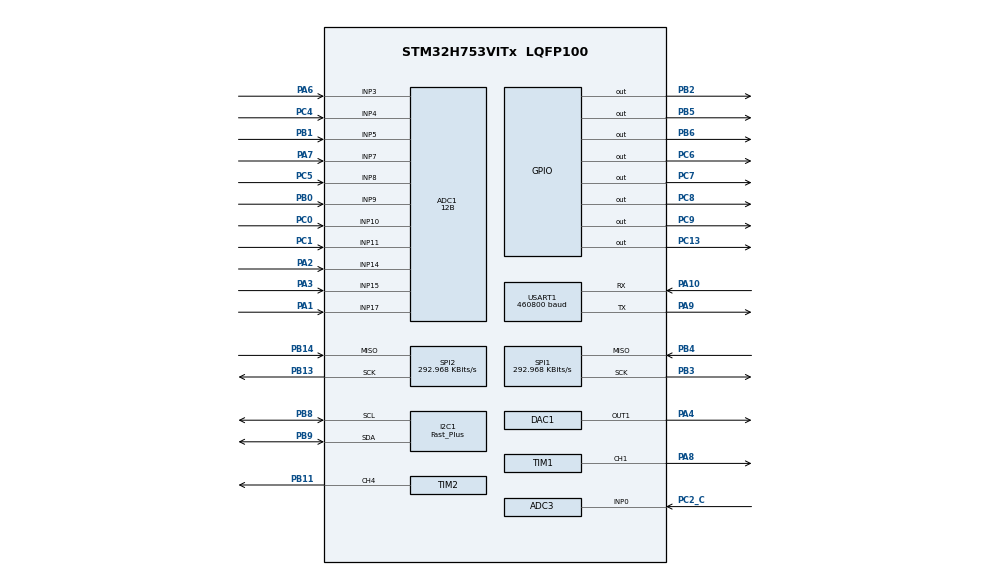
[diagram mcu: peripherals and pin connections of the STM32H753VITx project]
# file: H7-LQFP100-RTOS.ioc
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ADC1.Channel-0\#ChannelRegularConversion=ADC_CHANNEL_3
ADC1.Channel-1\#ChannelRegularConversion=ADC_CHANNEL_4
ADC1.Channel-10\#ChannelRegularConversion=ADC_CHANNEL_17
ADC1.Channel-2\#ChannelRegularConversion=ADC_CHANNEL_5
ADC1.Channel-3\#ChannelRegularConversion=ADC_CHANNEL_7
ADC1.Channel-4\#ChannelRegularConversion=ADC_CHANNEL_8
ADC1.Channel-5\#ChannelRegularConversion=ADC_CHANNEL_9
ADC1.Channel-6\#ChannelRegularConversion=ADC_CHANNEL_10
ADC1.Channel-7\#ChannelRegularConversion=ADC_CHANNEL_11
ADC1.Channel-8\#ChannelRegularConversion=ADC_CHANNEL_14
ADC1.Channel-9\#ChannelRegularConversion=ADC_CHANNEL_15
ADC1.ClockPrescaler=ADC_CLOCK_ASYNC_DIV2
ADC1.ClockPrescalerADC3=ADC_CLOCK_ASYNC_DIV2
ADC1.ContinuousConvMode=ENABLE
ADC1.ConversionDataManagement=ADC_CONVERSIONDATA_DMA_CIRCULAR
ADC1.NbrOfConversion=11
ADC1.NbrOfConversionFlag=1
ADC1.OffsetNumber-0\#ChannelRegularConversion=ADC_OFFSET_NONE
ADC1.OffsetNumber-1\#ChannelRegularConversion=ADC_OFFSET_NONE
ADC1.OffsetNumber-10\#ChannelRegularConversion=ADC_OFFSET_NONE
ADC1.OffsetNumber-2\#ChannelRegularConversion=ADC_OFFSET_NONE
ADC1.OffsetNumber-3\#ChannelRegularConversion=ADC_OFFSET_NONE
ADC1.OffsetNumber-4\#ChannelRegularConversion=ADC_OFFSET_NONE
ADC1.OffsetNumber-5\#ChannelRegularConversion=ADC_OFFSET_NONE
ADC1.OffsetNumber-6\#ChannelRegularConversion=ADC_OFFSET_NONE
ADC1.OffsetNumber-7\#ChannelRegularConversion=ADC_OFFSET_NONE
ADC1.OffsetNumber-8\#ChannelRegularConversion=ADC_OFFSET_NONE
ADC1.OffsetNumber-9\#ChannelRegularConversion=ADC_OFFSET_NONE
ADC1.OffsetSignedSaturation-0\#ChannelRegularConversion=DISABLE
ADC1.Overrun=ADC_OVR_DATA_OVERWRITTEN
ADC1.Rank-0\#ChannelRegularConversion=1
ADC1.Rank-1\#ChannelRegularConversion=2
ADC1.Rank-10\#ChannelRegularConversion=11
ADC1.Rank-2\#ChannelRegularConversion=3
ADC1.Rank-3\#ChannelRegularConversion=4
ADC1.Rank-4\#ChannelRegularConversion=5
ADC1.Rank-5\#ChannelRegularConversion=6
ADC1.Rank-6\#ChannelRegularConversion=7
ADC1.Rank-7\#ChannelRegularConversion=8
ADC1.Rank-8\#ChannelRegularConversion=9
ADC1.Rank-9\#ChannelRegularConversion=10
ADC1.Resolution=ADC_RESOLUTION_12B
ADC1.SamplingTime-0\#ChannelRegularConversion=ADC_SAMPLETIME_810CYCLES_5
ADC1.SamplingTime-1\#ChannelRegularConversion=ADC_SAMPLETIME_810CYCLES_5
ADC1.SamplingTime-10\#ChannelRegularConversion=ADC_SAMPLETIME_810CYCLES_5
ADC1.SamplingTime-2\#ChannelRegularConversion=ADC_SAMPLETIME_810CYCLES_5
ADC1.SamplingTime-3\#ChannelRegularConversion=ADC_SAMPLETIME_810CYCLES_5
ADC1.SamplingTime-4\#ChannelRegularConversion=ADC_SAMPLETIME_810CYCLES_5
ADC1.SamplingTime-5\#ChannelRegularConversion=ADC_SAMPLETIME_810CYCLES_5
ADC1.SamplingTime-6\#ChannelRegularConversion=ADC_SAMPLETIME_810CYCLES_5
ADC1.SamplingTime-7\#ChannelRegularConversion=ADC_SAMPLETIME_810CYCLES_5
ADC1.SamplingTime-8\#ChannelRegularConversion=ADC_SAMPLETIME_810CYCLES_5
ADC1.SamplingTime-9\#ChannelRegularConversion=ADC_SAMPLETIME_810CYCLES_5
ADC1.master=1
ADC3.Channel-0\#ChannelRegularConversion=ADC_CHANNEL_TEMPSENSOR
ADC3.Channel-1\#ChannelRegularConversion=ADC_CHANNEL_VREFINT
ADC3.Channel-2\#ChannelRegularConversion=ADC_CHANNEL_0
ADC3.ClockPrescalerADC3=ADC_CLOCK_ASYNC_DIV2
ADC3.ContinuousConvMode=ENABLE
ADC3.ConversionDataManagement=ADC_CONVERSIONDATA_DMA_CIRCULAR
ADC3.EnableAnalogWatchDog1=false
ADC3.NbrOfConversion=3
ADC3.NbrOfConversionFlag=1
ADC3.OffsetNumber-0\#ChannelRegularConversion=ADC_OFFSET_NONE
ADC3.OffsetNumber-1\#ChannelRegularConversion=ADC_OFFSET_NONE
ADC3.OffsetNumber-2\#ChannelRegularConversion=ADC_OFFSET_NONE
ADC3.OffsetSignedSaturation-0\#ChannelRegularConversion=DISABLE
ADC3.Overrun=ADC_OVR_DATA_OVERWRITTEN
ADC3.Rank-0\#ChannelRegularConversion=1
ADC3.Rank-1\#ChannelRegularConversion=2
ADC3.Rank-2\#ChannelRegularConversion=3
ADC3.Resolution=ADC_RESOLUTION_12B
ADC3.SamplingTime-0\#ChannelRegularConversion=ADC_SAMPLETIME_810CYCLES_5
ADC3.SamplingTime-1\#ChannelRegularConversion=ADC_SAMPLETIME_810CYCLES_5
ADC3.SamplingTime-2\#ChannelRegularConversion=ADC_SAMPLETIME_810CYCLES_5
CORTEX_M7.AccessPermission-Cortex_Memory_Protection_Unit_Region1_Settings=MPU_REGION_FULL_ACCESS
CORTEX_M7.BaseAddress-Cortex_Memory_Protection_Unit_Region0_Settings=0x00
CORTEX_M7.BaseAddress-Cortex_Memory_Protection_Unit_Region1_Settings=0x081C0000
CORTEX_M7.CPU_DCache=Disabled
CORTEX_M7.CPU_ICache=Disabled
CORTEX_M7.DisableExec-Cortex_Memory_Protection_Unit_Region0_Settings=MPU_INSTRUCTION_ACCESS_DISABLE
CORTEX_M7.Enable-Cortex_Memory_Protection_Unit_Region0_Settings=MPU_REGION_ENABLE
CORTEX_M7.Enable-Cortex_Memory_Protection_Unit_Region1_Settings=MPU_REGION_ENABLE
CORTEX_M7.IsShareable-Cortex_Memory_Protection_Unit_Region0_Settings=MPU_ACCESS_SHAREABLE
CORTEX_M7.MPU_Control=__NULL
CORTEX_M7.Size-Cortex_Memory_Protection_Unit_Region0_Settings=MPU_REGION_SIZE_4GB
CORTEX_M7.Size-Cortex_Memory_Protection_Unit_Region1_Settings=MPU_REGION_SIZE_256KB
CORTEX_M7.SubRegionDisable-Cortex_Memory_Protection_Unit_Region0_Settings=0x87
CORTEX_M7.SubRegionDisable-Cortex_Memory_Protection_Unit_Region1_Settings=0x00
CORTEX_M7.TypeExtField-Cortex_Memory_Protection_Unit_Region1_Settings=MPU_TEX_LEVEL1
DAC1.DAC_Channel-DAC_OUT1=DAC_CHANNEL_1
DAC1.DAC_Trigger-DAC_OUT1=DAC_TRIGGER_T2_TRGO
Dma.ADC1.0.Direction=DMA_PERIPH_TO_MEMORY
Dma.ADC1.0.EventEnable=DISABLE
Dma.ADC1.0.FIFOMode=DMA_FIFOMODE_DISABLE
Dma.ADC1.0.Instance=DMA1_Stream0
Dma.ADC1.0.MemDataAlignment=DMA_MDATAALIGN_HALFWORD
Dma.ADC1.0.MemInc=DMA_MINC_ENABLE
Dma.ADC1.0.Mode=DMA_CIRCULAR
Dma.ADC1.0.PeriphDataAlignment=DMA_PDATAALIGN_HALFWORD
Dma.ADC1.0.PeriphInc=DMA_PINC_DISABLE
Dma.ADC1.0.Polarity=HAL_DMAMUX_REQ_GEN_RISING
Dma.ADC1.0.Priority=DMA_PRIORITY_LOW
Dma.ADC1.0.RequestNumber=1
Dma.ADC1.0.SignalID=NONE
Dma.ADC1.0.SyncEnable=DISABLE
Dma.ADC1.0.SyncPolarity=HAL_DMAMUX_SYNC_NO_EVENT
Dma.ADC1.0.SyncRequestNumber=1
Dma.ADC1.0.SyncSignalID=NONE
Dma.ADC3.1.Direction=DMA_PERIPH_TO_MEMORY
Dma.ADC3.1.EventEnable=DISABLE
Dma.ADC3.1.FIFOMode=DMA_FIFOMODE_DISABLE
Dma.ADC3.1.Instance=DMA1_Stream1
Dma.ADC3.1.MemDataAlignment=DMA_MDATAALIGN_HALFWORD
Dma.ADC3.1.MemInc=DMA_MINC_ENABLE
Dma.ADC3.1.Mode=DMA_CIRCULAR
Dma.ADC3.1.PeriphDataAlignment=DMA_PDATAALIGN_HALFWORD
Dma.ADC3.1.PeriphInc=DMA_PINC_DISABLE
Dma.ADC3.1.Polarity=HAL_DMAMUX_REQ_GEN_RISING
Dma.ADC3.1.Priority=DMA_PRIORITY_LOW
Dma.ADC3.1.RequestNumber=1
Dma.ADC3.1.SignalID=NONE
Dma.ADC3.1.SyncEnable=DISABLE
Dma.ADC3.1.SyncPolarity=HAL_DMAMUX_SYNC_NO_EVENT
Dma.ADC3.1.SyncRequestNumber=1
Dma.ADC3.1.SyncSignalID=NONE
Dma.DAC1_CH1.2.Direction=DMA_MEMORY_TO_PERIPH
Dma.DAC1_CH1.2.EventEnable=DISABLE
Dma.DAC1_CH1.2.FIFOMode=DMA_FIFOMODE_DISABLE
Dma.DAC1_CH1.2.Instance=DMA1_Stream5
Dma.DAC1_CH1.2.MemDataAlignment=DMA_MDATAALIGN_WORD
Dma.DAC1_CH1.2.MemInc=DMA_MINC_ENABLE
Dma.DAC1_CH1.2.Mode=DMA_CIRCULAR
Dma.DAC1_CH1.2.PeriphDataAlignment=DMA_PDATAALIGN_WORD
Dma.DAC1_CH1.2.PeriphInc=DMA_PINC_DISABLE
Dma.DAC1_CH1.2.Polarity=HAL_DMAMUX_REQ_GEN_RISING
Dma.DAC1_CH1.2.Priority=DMA_PRIORITY_LOW
Dma.DAC1_CH1.2.RequestNumber=1
Dma.DAC1_CH1.2.SignalID=NONE
Dma.DAC1_CH1.2.SyncEnable=DISABLE
Dma.DAC1_CH1.2.SyncPolarity=HAL_DMAMUX_SYNC_NO_EVENT
Dma.DAC1_CH1.2.SyncRequestNumber=1
Dma.DAC1_CH1.2.SyncSignalID=NONE
Dma.I2C1_RX.7.Direction=DMA_PERIPH_TO_MEMORY
Dma.I2C1_RX.7.EventEnable=DISABLE
Dma.I2C1_RX.7.FIFOMode=DMA_FIFOMODE_DISABLE
Dma.I2C1_RX.7.Instance=DMA1_Stream7
Dma.I2C1_RX.7.MemDataAlignment=DMA_MDATAALIGN_BYTE
Dma.I2C1_RX.7.MemInc=DMA_MINC_ENABLE
Dma.I2C1_RX.7.Mode=DMA_NORMAL
Dma.I2C1_RX.7.PeriphDataAlignment=DMA_PDATAALIGN_BYTE
Dma.I2C1_RX.7.PeriphInc=DMA_PINC_DISABLE
Dma.I2C1_RX.7.Polarity=HAL_DMAMUX_REQ_GEN_RISING
Dma.I2C1_RX.7.Priority=DMA_PRIORITY_VERY_HIGH
Dma.I2C1_RX.7.RequestNumber=1
Dma.I2C1_RX.7.SignalID=NONE
Dma.I2C1_RX.7.SyncEnable=DISABLE
Dma.I2C1_RX.7.SyncPolarity=HAL_DMAMUX_SYNC_NO_EVENT
Dma.I2C1_RX.7.SyncRequestNumber=1
Dma.I2C1_RX.7.SyncSignalID=NONE
Dma.I2C1_TX.6.Direction=DMA_MEMORY_TO_PERIPH
Dma.I2C1_TX.6.EventEnable=DISABLE
Dma.I2C1_TX.6.FIFOMode=DMA_FIFOMODE_DISABLE
Dma.I2C1_TX.6.Instance=DMA1_Stream6
Dma.I2C1_TX.6.MemDataAlignment=DMA_MDATAALIGN_BYTE
Dma.I2C1_TX.6.MemInc=DMA_MINC_ENABLE
Dma.I2C1_TX.6.Mode=DMA_NORMAL
Dma.I2C1_TX.6.PeriphDataAlignment=DMA_PDATAALIGN_BYTE
Dma.I2C1_TX.6.PeriphInc=DMA_PINC_DISABLE
Dma.I2C1_TX.6.Polarity=HAL_DMAMUX_REQ_GEN_RISING
Dma.I2C1_TX.6.Priority=DMA_PRIORITY_VERY_HIGH
Dma.I2C1_TX.6.RequestNumber=1
Dma.I2C1_TX.6.SignalID=NONE
Dma.I2C1_TX.6.SyncEnable=DISABLE
Dma.I2C1_TX.6.SyncPolarity=HAL_DMAMUX_SYNC_NO_EVENT
Dma.I2C1_TX.6.SyncRequestNumber=1
Dma.I2C1_TX.6.SyncSignalID=NONE
Dma.Request0=ADC1
Dma.Request1=ADC3
Dma.Request2=DAC1_CH1
Dma.Request3=USART1_TX
Dma.Request4=SPI2_RX
Dma.Request5=SPI1_RX
Dma.Request6=I2C1_TX
Dma.Request7=I2C1_RX
Dma.SPI1_RX.5.Direction=DMA_PERIPH_TO_MEMORY
Dma.SPI1_RX.5.EventEnable=DISABLE
Dma.SPI1_RX.5.FIFOMode=DMA_FIFOMODE_DISABLE
Dma.SPI1_RX.5.Instance=DMA1_Stream4
Dma.SPI1_RX.5.MemDataAlignment=DMA_MDATAALIGN_HALFWORD
Dma.SPI1_RX.5.MemInc=DMA_MINC_ENABLE
Dma.SPI1_RX.5.Mode=DMA_NORMAL
Dma.SPI1_RX.5.PeriphDataAlignment=DMA_PDATAALIGN_HALFWORD
Dma.SPI1_RX.5.PeriphInc=DMA_PINC_DISABLE
Dma.SPI1_RX.5.Polarity=HAL_DMAMUX_REQ_GEN_RISING
Dma.SPI1_RX.5.Priority=DMA_PRIORITY_LOW
Dma.SPI1_RX.5.RequestNumber=1
Dma.SPI1_RX.5.SignalID=NONE
Dma.SPI1_RX.5.SyncEnable=DISABLE
Dma.SPI1_RX.5.SyncPolarity=HAL_DMAMUX_SYNC_NO_EVENT
Dma.SPI1_RX.5.SyncRequestNumber=1
Dma.SPI1_RX.5.SyncSignalID=NONE
Dma.SPI2_RX.4.Direction=DMA_PERIPH_TO_MEMORY
Dma.SPI2_RX.4.EventEnable=DISABLE
Dma.SPI2_RX.4.FIFOMode=DMA_FIFOMODE_DISABLE
Dma.SPI2_RX.4.Instance=DMA1_Stream3
Dma.SPI2_RX.4.MemDataAlignment=DMA_MDATAALIGN_HALFWORD
Dma.SPI2_RX.4.MemInc=DMA_MINC_ENABLE
Dma.SPI2_RX.4.Mode=DMA_NORMAL
Dma.SPI2_RX.4.PeriphDataAlignment=DMA_PDATAALIGN_HALFWORD
Dma.SPI2_RX.4.PeriphInc=DMA_PINC_DISABLE
Dma.SPI2_RX.4.Polarity=HAL_DMAMUX_REQ_GEN_RISING
Dma.SPI2_RX.4.Priority=DMA_PRIORITY_LOW
Dma.SPI2_RX.4.RequestNumber=1
Dma.SPI2_RX.4.SignalID=NONE
Dma.SPI2_RX.4.SyncEnable=DISABLE
Dma.SPI2_RX.4.SyncPolarity=HAL_DMAMUX_SYNC_NO_EVENT
Dma.SPI2_RX.4.SyncRequestNumber=1
Dma.SPI2_RX.4.SyncSignalID=NONE
Dma.USART1_TX.3.Direction=DMA_MEMORY_TO_PERIPH
Dma.USART1_TX.3.EventEnable=DISABLE
Dma.USART1_TX.3.FIFOMode=DMA_FIFOMODE_DISABLE
Dma.USART1_TX.3.Instance=DMA1_Stream2
Dma.USART1_TX.3.MemDataAlignment=DMA_MDATAALIGN_BYTE
Dma.USART1_TX.3.MemInc=DMA_MINC_ENABLE
Dma.USART1_TX.3.Mode=DMA_NORMAL
Dma.USART1_TX.3.PeriphDataAlignment=DMA_PDATAALIGN_BYTE
Dma.USART1_TX.3.PeriphInc=DMA_PINC_DISABLE
Dma.USART1_TX.3.Polarity=HAL_DMAMUX_REQ_GEN_RISING
Dma.USART1_TX.3.Priority=DMA_PRIORITY_LOW
Dma.USART1_TX.3.RequestNumber=1
Dma.USART1_TX.3.SignalID=NONE
Dma.USART1_TX.3.SyncEnable=DISABLE
Dma.USART1_TX.3.SyncPolarity=HAL_DMAMUX_SYNC_NO_EVENT
Dma.USART1_TX.3.SyncRequestNumber=1
Dma.USART1_TX.3.SyncSignalID=NONE
FREERTOS.INCLUDE_xEventGroupSetBitFromISR=1
FREERTOS.Tasks01=PMT_task,54,128,PMT_init,Default,NULL,Static,PMT_taskBuffer,PMT_taskControlBlock;ERPA_task,55,128,ERPA_init,Default,NULL,Static,ERPA_taskBuffer,ERPA_taskControlBlock;HK_task,52,128,HK_init,Default,NULL,Static,HK_taskBuffer,HK_taskControlBlock;AUTOINIT_task,24,128,AUTOINIT_init,Default,NULL,Static,AUTOINIT_taskBuffer,AUTOINIT_taskControlBlock;AUTODEINIT_task,24,128,AUTODEINIT_init,Default,NULL,Static,AUTODEINIT_taskBuffer,AUTODEINIT_taskControlBlock;Voltage_Monitor,53,128,Voltage_Monitor_init,Default,NULL,Static,Voltage_MonitorBuffer,Voltage_MonitorControlBlock;STOP_task,24,128,STOP_init,Default,NULL,Static,STOP_taskBuffer,STOP_taskControlBlock;Science_task,55,128,Science_init,Default,NULL,Static,Science_taskBuffer,Science_taskControlBlock;Idle_task,55,128,Idle_init,Default,NULL,Static,Idle_taskBuffer,Idle_taskControlBlock;Sync_task,24,128,Sync_init,Default,NULL,Static,Sync_taskBuffer,Sync_taskControlBlock
FREERTOS.configCHECK_FOR_STACK_OVERFLOW=1
FREERTOS.configENABLE_FPU=1
FREERTOS.configUSE_TICK_HOOK=1
I2C1.I2C_Speed_Mode=I2C_Fast_Plus
I2C1.Timing=0x00100517
IWDG1.Prescaler=IWDG_PRESCALER_64
IWDG1.Reload=2499
IWDG1.Window=2499
Mcu.Family=STM32H7
Mcu.Name=STM32H753VITx
Mcu.Package=LQFP100
NVIC.DMA1_Stream0_IRQn=true\:5\:0\:false\:false\:true\:true\:false\:true\:true
NVIC.DMA1_Stream1_IRQn=true\:5\:0\:false\:false\:true\:true\:false\:true\:true
NVIC.DMA1_Stream2_IRQn=true\:5\:0\:false\:false\:true\:true\:false\:true\:true
NVIC.DMA1_Stream3_IRQn=true\:5\:0\:false\:false\:true\:true\:false\:true\:true
NVIC.DMA1_Stream4_IRQn=true\:5\:0\:false\:false\:true\:true\:false\:true\:true
NVIC.DMA1_Stream5_IRQn=true\:5\:0\:false\:false\:true\:false\:false\:true\:true
NVIC.DMA1_Stream6_IRQn=true\:5\:0\:false\:false\:true\:true\:false\:true\:true
NVIC.DMA1_Stream7_IRQn=true\:5\:0\:false\:false\:true\:true\:false\:true\:true
NVIC.FLASH_IRQn=true\:5\:0\:false\:false\:true\:true\:true\:true\:true
NVIC.I2C1_ER_IRQn=true\:5\:0\:false\:false\:true\:true\:true\:true\:true
NVIC.I2C1_EV_IRQn=true\:5\:0\:false\:false\:true\:true\:true\:true\:true
NVIC.PriorityGroup=NVIC_PRIORITYGROUP_4
NVIC.SPI1_IRQn=true\:5\:0\:false\:false\:true\:true\:false\:true\:true
NVIC.SPI2_IRQn=true\:5\:0\:false\:false\:true\:true\:true\:true\:true
NVIC.TIM1_BRK_IRQn=true\:5\:0\:false\:false\:true\:true\:true\:true\:true
NVIC.TIM1_CC_IRQn=true\:5\:0\:false\:false\:true\:true\:true\:true\:true
NVIC.TIM1_TRG_COM_IRQn=true\:5\:0\:false\:false\:true\:true\:true\:true\:true
NVIC.TIM1_UP_IRQn=true\:5\:0\:false\:false\:true\:true\:true\:true\:true
NVIC.TIM2_IRQn=true\:5\:0\:false\:false\:true\:true\:true\:true\:true
NVIC.TIM3_IRQn=true\:5\:0\:false\:false\:true\:true\:true\:true\:true
NVIC.TIM6_DAC_IRQn=true\:5\:0\:true\:false\:true\:false\:false\:true\:true
NVIC.TimeBase=TIM6_DAC_IRQn
NVIC.TimeBaseIP=TIM6
NVIC.USART1_IRQn=true\:5\:0\:false\:false\:true\:true\:true\:true\:true
PA1.Mode=IN17-Single-Ended
PA1.Signal=ADC1_INP17
PA10.Mode=Asynchronous
PA10.Signal=USART1_RX
PA2.Signal=ADCx_INP14
PA3.Signal=ADCx_INP15
PA4.Signal=COMP_DAC11_group
PA6.Signal=ADCx_INP3
PA7.Signal=ADCx_INP7
PA8.Signal=S_TIM1_CH1
PA9.Mode=Asynchronous
PA9.Signal=USART1_TX
PB0.Signal=ADCx_INP9
PB1.Signal=ADCx_INP5
PB11.Signal=S_TIM2_CH4
PB13.Mode=RX_Only_Simplex_Unidirect_Master
PB13.Signal=SPI2_SCK
PB14.Mode=RX_Only_Simplex_Unidirect_Master
PB14.Signal=SPI2_MISO
PB2.GPIO_PuPd=GPIO_PULLDOWN
PB2.Signal=GPIO_Output
PB3\ (JTDO/TRACESWO).Mode=RX_Only_Simplex_Unidirect_Master
PB3\ (JTDO/TRACESWO).Signal=SPI1_SCK
PB4\ (NJTRST).Mode=RX_Only_Simplex_Unidirect_Master
PB4\ (NJTRST).Signal=SPI1_MISO
PB5.GPIO_PuPd=GPIO_PULLDOWN
PB5.Signal=GPIO_Output
PB6.GPIO_PuPd=GPIO_PULLDOWN
PB6.Signal=GPIO_Output
PB8.Mode=I2C
PB8.Signal=I2C1_SCL
PB9.Mode=I2C
PB9.Signal=I2C1_SDA
PC0.Signal=ADCx_INP10
PC1.Signal=ADCx_INP11
PC13.GPIO_PuPd=GPIO_PULLDOWN
PC13.Signal=GPIO_Output
PC14-OSC32_IN\ (OSC32_IN).Mode=LSE-External-Oscillator
PC14-OSC32_IN\ (OSC32_IN).Signal=RCC_OSC32_IN
PC15-OSC32_OUT\ (OSC32_OUT).Mode=LSE-External-Oscillator
PC15-OSC32_OUT\ (OSC32_OUT).Signal=RCC_OSC32_OUT
PC2_C.Mode=IN0-Single-Ended
PC2_C.Signal=ADC3_INP0
PC4.Signal=ADCx_INP4
PC5.Signal=ADCx_INP8
PC6.GPIO_PuPd=GPIO_PULLDOWN
PC6.Signal=GPIO_Output
PC7.GPIO_PuPd=GPIO_PULLDOWN
PC7.Signal=GPIO_Output
PC8.GPIO_PuPd=GPIO_PULLDOWN
PC8.Signal=GPIO_Output
PC9.GPIO_PuPd=GPIO_PULLDOWN
PC9.Signal=GPIO_Output
PH0-OSC_IN\ (PH0).Mode=HSE-External-Oscillator
PH0-OSC_IN\ (PH0).Signal=RCC_OSC_IN
PH1-OSC_OUT\ (PH1).Mode=HSE-External-Oscillator
PH1-OSC_OUT\ (PH1).Signal=RCC_OSC_OUT
ProjectManager.HeapSize=0x200
ProjectManager.StackSize=0x400
ProjectManager.TargetToolchain=STM32CubeIDE
RAMECC.Instance-RAMECC1_Monitor1=RAMECC1_Monitor1
RAMECC.Instance-RAMECC1_Monitor2=RAMECC1_Monitor2
RAMECC.Instance-RAMECC1_Monitor3=RAMECC1_Monitor3
RAMECC.Instance-RAMECC1_Monitor4=RAMECC1_Monitor4
RAMECC.Instance-RAMECC1_Monitor5=RAMECC1_Monitor5
RAMECC.Instance-RAMECC2_Monitor1=RAMECC2_Monitor1
RAMECC.Instance-RAMECC2_Monitor2=RAMECC2_Monitor2
RAMECC.Instance-RAMECC2_Monitor3=RAMECC2_Monitor3
RAMECC.Instance-RAMECC2_Monitor4=RAMECC2_Monitor4
RAMECC.Instance-RAMECC2_Monitor5=RAMECC2_Monitor5
RAMECC.Instance-RAMECC3_Monitor1=RAMECC3_Monitor1
RAMECC.Instance-RAMECC3_Monitor2=RAMECC3_Monitor2
RCC.ADCFreq_Value=18750000
RCC.APB1Freq_Value=37500000
RCC.APB2Freq_Value=75000000
RCC.APB3Freq_Value=75000000
RCC.APB4Freq_Value=75000000
RCC.CortexFreq_Value=75000000
RCC.D2PPRE1=RCC_APB1_DIV2
RCC.DIVM1=4
RCC.DIVM2=4
RCC.DIVM3=4
RCC.DIVN1=24
RCC.DIVN2=24
RCC.DIVN3=24
RCC.DIVP2=8
RCC.HCLKFreq_Value=75000000
RCC.HSIDiv=RCC_PLLSAIDIVR_2
RCC.PLL2FRACN=0
RCC.PLL2_VCI_Range-AdvancedSettings=RCC_PLL2VCIRANGE_0
RCC.PLL3FRACN=0
RCC.PLLFRACN=0
RCC.PLLSourceVirtual=RCC_PLLSOURCE_HSE
RCC.ProductRev=revV
RCC.RCC_RTC_Clock_Source_FROM_HSE=RCC_RTCCLKSOURCE_HSE_DIV25
RCC.RTCClockSelection=RCC_RTCCLKSOURCE_HSE_DIV25
RCC.SYSCLKFreq_VALUE=75000000
RCC.SYSCLKSource=RCC_SYSCLKSOURCE_PLLCLK
RCC.USART16CLockSelection=RCC_USART16CLKSOURCE_HSI
RCC.USBFreq_Value=75000000
RTC.AsynchPrediv=100-1
RTC.SynchPrediv=10000-1
SH.ADCx_INP10.0=ADC1_INP10,IN10-Single-Ended
SH.ADCx_INP11.0=ADC1_INP11,IN11-Single-Ended
SH.ADCx_INP14.0=ADC1_INP14,IN14-Single-Ended
SH.ADCx_INP15.0=ADC1_INP15,IN15-Single-Ended
SH.ADCx_INP3.0=ADC1_INP3,IN3-Single-Ended
SH.ADCx_INP4.0=ADC1_INP4,IN4-Single-Ended
SH.ADCx_INP5.0=ADC1_INP5,IN5-Single-Ended
SH.ADCx_INP7.0=ADC1_INP7,IN7-Single-Ended
SH.ADCx_INP8.0=ADC1_INP8,IN8-Single-Ended
SH.ADCx_INP9.0=ADC1_INP9,IN9-Single-Ended
SH.COMP_DAC11_group.0=DAC1_OUT1,DAC_OUT1
SH.S_TIM1_CH1.0=TIM1_CH1,PWM Generation1 CH1
SH.S_TIM2_CH4.0=TIM2_CH4,PWM Generation4 CH4
SPI1.BaudRatePrescaler=SPI_BAUDRATEPRESCALER_256
SPI1.CalculateBaudRate=292.968 KBits/s
SPI1.DataSize=SPI_DATASIZE_16BIT
SPI1.Direction=SPI_DIRECTION_2LINES_RXONLY
SPI1.Mode=SPI_MODE_MASTER
SPI1.VirtualType=VM_MASTER
SPI2.BaudRatePrescaler=SPI_BAUDRATEPRESCALER_256
SPI2.CalculateBaudRate=292.968 KBits/s
SPI2.DataSize=SPI_DATASIZE_16BIT
SPI2.Direction=SPI_DIRECTION_2LINES_RXONLY
SPI2.Mode=SPI_MODE_MASTER
SPI2.VirtualType=VM_MASTER
TIM1.Channel-PWM\ Generation1\ CH1=TIM_CHANNEL_1
TIM1.Period=62500-1
TIM1.Prescaler=75-1
TIM1.Pulse-PWM\ Generation1\ CH1=480-1
TIM2.AutoReloadPreload=TIM_AUTORELOAD_PRELOAD_ENABLE
TIM2.Channel-PWM\ Generation4\ CH4=TIM_CHANNEL_4
TIM2.Period=3125-1
TIM2.Prescaler=75-1
TIM2.TIM_MasterOutputTrigger=TIM_TRGO_UPDATE
TIM3.Period=35000-1
TIM3.Prescaler=7500-1
USART1.BaudRate=460800
USART1.VirtualMode-Asynchronous=VM_ASYNC
VP_ADC3_TempSens_Input.Mode=IN-TempSens
VP_ADC3_Vref_Input.Mode=IN-Vrefint
VP_FREERTOS_VS_CMSIS_V2.Mode=CMSIS_V2
VP_IWDG1_VS_IWDG.Mode=IWDG_Activate
VP_RAMECC_VS_D1_1.Mode=RAMECC1_Monitor1
VP_RAMECC_VS_D1_2.Mode=RAMECC1_Monitor2
VP_RAMECC_VS_D1_3.Mode=RAMECC1_Monitor3
VP_RAMECC_VS_D1_4.Mode=RAMECC1_Monitor4
VP_RAMECC_VS_D1_5.Mode=RAMECC1_Monitor5
VP_RAMECC_VS_D2_1.Mode=RAMECC2_Monitor1
VP_RAMECC_VS_D2_2.Mode=RAMECC2_Monitor2
VP_RAMECC_VS_D2_3.Mode=RAMECC2_Monitor3
VP_RAMECC_VS_D2_4.Mode=RAMECC2_Monitor4
VP_RAMECC_VS_D2_5.Mode=RAMECC2_Monitor5
VP_RAMECC_VS_D3_1.Mode=RAMECC3_Monitor1
VP_RAMECC_VS_D3_2.Mode=RAMECC3_Monitor2
VP_RTC_VS_RTC_Activate.Mode=RTC_Enabled
VP_RTC_VS_RTC_Calendar.Mode=RTC_Calendar
VP_SYS_VS_tim6.Mode=TIM6
VP_TIM1_VS_ClockSourceINT.Mode=Internal
VP_TIM2_VS_ClockSourceINT.Mode=Internal
VP_TIM3_VS_ClockSourceINT.Mode=Internal
board=custom

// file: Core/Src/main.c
/* USER CODE BEGIN Header */
/**
 ******************************************************************************
 * @file           : main.c
 * @author 		   : Jared Morrison
 * @version 	   : 1.0.0
 * @brief          : Main program body
 ******************************************************************************
 * @attention
 *
 * Copyright (c) 2024 STMicroelectronics.
 * All rights reserved.
 *
 * This software is licensed under terms that can be found in the LICENSE file
 * in the root directory of this software component.
 * If no LICENSE file comes with this software, it is provided AS-IS.
 *
 ******************************************************************************
 */
/* USER CODE END Header */
#include "version_info.h"
#include "main.h"
#include "cmsis_os.h"
#include "adc.h"
#include "dac.h"
#include "dma.h"
#include "i2c.h"
#include "iwdg.h"
#include "ramecc.h"
#include "rtc.h"
#include "spi.h"
#include "tim.h"
#include "usart.h"
#include "gpio.h"

/* USER CODE BEGIN PTD */

/**
 * @brief Enumeration of predefined DAC values.
 *        Represents specific output values for the DAC.
 */
typedef enum
{
    DAC_VALUE_0 = 0,
    DAC_VALUE_620 = 620,
    DAC_VALUE_1241 = 1241,
    DAC_VALUE_1861 = 1861,
    DAC_VALUE_2482 = 2482,
    DAC_VALUE_3103 = 3103,
    DAC_VALUE_3723 = 3723,
    DAC_VALUE_4095 = 4095
} DAC_VALUES;

/**
 * @brief Enumeration of accepted command codes.
 *        Defines a set of command values for controlling system power, modes, and error handling.
 */
typedef enum
{
	CMD_SDN1_ON = 0x10,
	CMD_SDN1_OFF = 0x00,
	CMD_SYS_ON = 0x11,
	CMD_SYS_OFF = 0x01,
	CMD_5V_ON = 0x12,
	CMD_5V_OFF = 0x02,
	CMD_N3V3_ON = 0x13,
	CMD_N3V3_OFF = 0x03,
	CMD_N5V_ON = 0x14,
	CMD_N5V_OFF = 0x04,
	CMD_15V_ON = 0x15,
	CMD_15V_OFF = 0x05,
	CMD_N200V_ON = 0x16,
	CMD_N200V_OFF = 0x06,
	CMD_N800V_ON = 0x17,
	CMD_N800V_OFF = 0x07,
	CMD_AUTOSWEEP_ON = 0x18,
	CMD_AUTOSWEEP_OFF = 0x08,
	CMD_ERPA_ON = 0x19,
	CMD_ERPA_OFF = 0x09,
	CMD_PMT_ON = 0x1A,
	CMD_PMT_OFF = 0x0A,
	CMD_HK_ON = 0x1B,
	CMD_HK_OFF = 0x0B,
	CMD_STEP_UP = 0x1C,
	CMD_STEP_DOWN = 0x0C,
	CMD_FACTOR_UP = 0x1D,
	CMD_FACTOR_DOWN = 0x0D,
	CMD_AUTO_INIT = 0x1E,
	CMD_AUTO_DEINIT = 0x0E,
	CMD_SYNC_MODE = 0xA0,
	CMD_SCIENCE_MODE = 0xA1,
	CMD_IDLE_MODE = 0xA2,
	CMD_ENTER_STOP = 0xA3,
	CMD_RESET_ERROR_COUNTERS = 0xA4,
	CMD_SEND_PREVIOUS_ERROR = 0xA5,
	CMD_SEND_VERSION_PACKET = 0xA6,
	CMD_SEND_VERSION_INFO = 0xA7,
	CMD_UPDATE_FIRMWARE = 0x2A,
	CMD_ST_BL_SYNC = 0x7F
}ACCEPTED_COMMANDS;

typedef  void (*pFunction)(void);
/* USER CODE END PTD */

/* USER CODE BEGIN PD */
//#define HK_100MS_COUNTER_MAX 32
#define HK_100MS_COUNTER_MAX 3200

#define ACK 0xFF
#define NACK 0x00

#define BOOTLOADER_FLAG_ADDR ((uint32_t*)0x2001FFF0)
#define BOOTLOADER_FLAG_VALUE 0xDEADBEEF
#define BOOTLOADER_FLAG_OFFSET 1000
#define BOOTLOADER_ADDRESS 0x1FF09800
/* USER CODE END PD */

/* USER CODE BEGIN PV */

/**
 * @brief Array of GPIO pin configurations.
 *        Represents the mapping of specific GPIO ports and pins to system components.
 */
const gpio_pins gpios[] =
{
		{ GPIOB, GPIO_PIN_2 	},	// 0 -- SDN1
		{ GPIOB, GPIO_PIN_5 	},	// 1 -- SYS_ON
		{ GPIOC, GPIO_PIN_7 	},	// 2 -- 5v_EN
		{ GPIOC, GPIO_PIN_6 	},	// 3 -- N3V3_EN
		{ GPIOC, GPIO_PIN_8 	},	// 4 -- N5V_EN
		{ GPIOC, GPIO_PIN_9 	},	// 5 -- 15V_EN
		{ GPIOC, GPIO_PIN_13 	},	// 6 -- N150V_EN
		{ GPIOB, GPIO_PIN_6 	}	// 7 -- 800HVON
};

/**
 * @brief Array of DAC output values representing sweeping up and down voltages.
 *
 * DAC_OUT alternates between specified DAC values to control the output voltage.
 * The first half sweeps up, reaching a maximum at DAC_VALUE_4095, then sweeps down.
 */
uint32_t DAC_OUT[DAC_OUT_ARRAY_SIZE] =
{
		DAC_VALUE_0, DAC_VALUE_0,		// |	Sweeping Up
		DAC_VALUE_620, DAC_VALUE_620,	// |
		DAC_VALUE_1241, DAC_VALUE_1241,	// |
		DAC_VALUE_1861, DAC_VALUE_1861,	// |
		DAC_VALUE_2482, DAC_VALUE_2482,	// |
		DAC_VALUE_3103, DAC_VALUE_3103,	// |
		DAC_VALUE_3723, DAC_VALUE_3723,	// V

		DAC_VALUE_4095, DAC_VALUE_4095,	// --	Max Sweep
		DAC_VALUE_4095, DAC_VALUE_4095, // --

		DAC_VALUE_3723, DAC_VALUE_3723,	// |	Sweeping Down
		DAC_VALUE_3103, DAC_VALUE_3103,	// |
		DAC_VALUE_2482, DAC_VALUE_2482,	// |
		DAC_VALUE_1861, DAC_VALUE_1861,	// |
		DAC_VALUE_1241, DAC_VALUE_1241,	// |
		DAC_VALUE_620, DAC_VALUE_620,	// |
		DAC_VALUE_0, DAC_VALUE_0		// V
}; // For 3.3 volts

osEventFlagsId_t packet_event_flags;
osEventFlagsId_t utility_event_flags;
osEventFlagsId_t mode_event_flags;

unsigned char UART_RX_BUFFER[UART_RX_BUFFER_SIZE];
volatile uint8_t HK_ENABLED = DISABLED;
volatile uint8_t ERPA_ENABLED = DISABLED;
volatile uint8_t step = 0;
volatile uint32_t cadence = 3125;
volatile uint32_t uptime_millis = 0;
volatile uint32_t HK_100_ms_counter = 0;
volatile uint8_t IDLING = 1;
volatile uint8_t startup_pmt_sent = 0;
volatile uint8_t startup_hk_sent = 0;

extern int _estack;
uint32_t *bootloader_flag;
pFunction JumpToApplication;
uint32_t JumpAddress;

__attribute__((section(".app_crc"))) __attribute__((used))
const uint32_t app_crc_placeholder = 0xFFFFFFFF;
/* USER CODE END PV */

void SystemClock_Config(void);
void PeriphCommonClock_Config(void);
void MX_FREERTOS_Init(void);
/* USER CODE BEGIN PFP */
void system_setup();
void init_flash_ecc();
/* USER CODE END PFP */

/* USER CODE BEGIN 0 */

/**
 * @brief Prepares for system reset and jump to bootloader
 */
void SetBootloaderFlag() {
	__disable_irq();
//	*bootloader_flag = BOOTLOADER_FLAG_VALUE;
	*BOOTLOADER_FLAG_ADDR = BOOTLOADER_FLAG_VALUE;
	HAL_UART_DeInit(&huart1);
	HAL_NVIC_SystemReset();
}

/**
 * @brief Recognizes if we want to jump to the bootloader and does so
 */
void JumpToBootloader(void)
{
	bootloader_flag = (uint32_t*) (&_estack - BOOTLOADER_FLAG_OFFSET); // below top of stack
	if (*bootloader_flag == BOOTLOADER_FLAG_VALUE) {
		*bootloader_flag = 0;
		/* Jump to system memory bootloader */
		JumpAddress = *(__IO uint32_t*) (BOOTLOADER_ADDRESS + 4);
		JumpToApplication = (pFunction) JumpAddress;
		__set_MSP(*(__IO uint32_t*) BOOTLOADER_ADDRESS);
		JumpToApplication();
	}
		*bootloader_flag = 0; // So next boot won't be affected
}

/**
 * @brief Callback function for handling ECC correction in flash memory.
 *        Detects and handles single-bit flash ECC errors.
 */
void HAL_FLASHEx_EccCorrectionCallback()
{
	ERROR_STRUCT error;
	error.category = EC_seu;
	error.detail = ED_single_bit_error_flash;
	handle_error(error);
}

/**
 * @brief Callback function for handling ECC detection in flash memory.
 *        Detects and handles double-bit flash ECC errors.
 */
void HAL_FLASHEx_EccDetectionCallback()
{
	ERROR_STRUCT error;
	error.category = EC_seu;
	error.detail = ED_double_bit_error_flash;
	handle_error(error);
}

/**
 * @brief Output compare callback for handling timer events.
 *        Sets event flags based on the triggered timer and manages housekeeping tasks.
 *
 * @param htim Pointer to the timer handle triggering the callback.
 */
void HAL_TIM_OC_DelayElapsedCallback(TIM_HandleTypeDef *htim)
{
	if (htim == &htim1)
	{
		// Not the prettiest or best way to go about it, but
		// this will make a startup packet for HK and PMT (NO ERPA STARTUP) when right when science mode is triggered
		if (startup_pmt_sent == 0)
		{
			pmt_seq = 0;
			startup_pmt_sent = 1;
			hk_seq = 0;
			osEventFlagsSet(packet_event_flags, HK_FLAG);
		}
		osEventFlagsSet(packet_event_flags, PMT_FLAG);
	}
	else if (htim == &htim2)
	{
		if (ERPA_ENABLED)
		{
			osEventFlagsSet(packet_event_flags, ERPA_FLAG);
		}
		if (HK_100_ms_counter == HK_100MS_COUNTER_MAX)
		{
			osEventFlagsSet(utility_event_flags, VOLTAGE_MONITOR_FLAG);
			if (HK_ENABLED)
			{
				osEventFlagsSet(packet_event_flags, HK_FLAG);
			}
			HK_100_ms_counter = 0;
		}
		HK_100_ms_counter++;
	}
	else
	{
		// Unknown timer interrupt
	}
}

/**
 * @brief UART receive complete callback.
 *        Processes received commands to control GPIO pins and manage power rails.
 *
 * @param huart Pointer to the UART handle triggering the callback.
 */
void HAL_UART_RxCpltCallback(UART_HandleTypeDef *huart)
{
	HAL_UART_Receive_IT(&huart1, UART_RX_BUFFER, 1);
	uint8_t key_index = 0;
	unsigned char key = UART_RX_BUFFER[key_index];

	switch (key)
	{
	case CMD_SDN1_ON:
	{
		HAL_GPIO_WritePin(gpios[GPIOS_INDEX_SDN1].gpio, gpios[GPIOS_INDEX_SDN1].pin, GPIO_PIN_SET);
		break;
	}

	case CMD_SDN1_OFF:
	{
		HAL_GPIO_WritePin(gpios[GPIOS_INDEX_SDN1].gpio, gpios[GPIOS_INDEX_SDN1].pin, GPIO_PIN_RESET);
		break;
	}

	case CMD_SYS_ON:
	{
		HAL_GPIO_WritePin(gpios[GPIOS_INDEX_SYS].gpio, gpios[GPIOS_INDEX_SYS].pin, GPIO_PIN_SET);
		set_rail_monitor_enable(RAIL_2v5, ENABLED);
		break;
	}

	case CMD_SYS_OFF:
	{
		for (int i = GPIOS_INDEX_N800V; i > GPIOS_INDEX_SDN1; i--)
		{
			HAL_GPIO_WritePin(gpios[i].gpio, gpios[i].pin, GPIO_PIN_RESET);
		}

		for (int i = RAIL_n800v; i >= RAIL_2v5; i--)
		{
			set_rail_monitor_enable(i, DISABLED);
		}
		break;
	}

	case CMD_5V_ON:
	{
		HAL_GPIO_WritePin(gpios[GPIOS_INDEX_5V].gpio, gpios[GPIOS_INDEX_5V].pin, GPIO_PIN_SET);
		set_rail_monitor_enable(RAIL_5v, ENABLED);
		break;
	}

	case CMD_5V_OFF:
	{
		HAL_GPIO_WritePin(gpios[GPIOS_INDEX_5V].gpio, gpios[GPIOS_INDEX_5V].pin, GPIO_PIN_RESET);
		set_rail_monitor_enable(RAIL_5v, DISABLED);
		break;
	}

	case CMD_N3V3_ON:
	{
		HAL_GPIO_WritePin(gpios[GPIOS_INDEX_N3V3].gpio, gpios[GPIOS_INDEX_N3V3].pin, GPIO_PIN_SET);
		set_rail_monitor_enable(RAIL_n3v3, ENABLED);
		break;
	}

	case CMD_N3V3_OFF:
	{
		HAL_GPIO_WritePin(gpios[GPIOS_INDEX_N3V3].gpio, gpios[GPIOS_INDEX_N3V3].pin, GPIO_PIN_RESET);
		set_rail_monitor_enable(RAIL_n3v3, DISABLED);
		break;
	}

	case CMD_N5V_ON:
	{
		HAL_GPIO_WritePin(gpios[GPIOS_INDEX_N5V].gpio, gpios[GPIOS_INDEX_N5V].pin, GPIO_PIN_SET);
		set_rail_monitor_enable(RAIL_n5v, ENABLED);
		break;
	}

	case CMD_N5V_OFF:
	{
		HAL_GPIO_WritePin(gpios[GPIOS_INDEX_N5V].gpio, gpios[GPIOS_INDEX_N5V].pin, GPIO_PIN_RESET);
		set_rail_monitor_enable(RAIL_n5v, DISABLED);
		break;
	}

	case CMD_15V_ON:
	{
		HAL_GPIO_WritePin(gpios[GPIOS_INDEX_15V].gpio, gpios[GPIOS_INDEX_15V].pin, GPIO_PIN_SET);
		set_rail_monitor_enable(RAIL_15v, ENABLED);
		break;
	}

	case CMD_15V_OFF:
	{
		HAL_GPIO_WritePin(gpios[GPIOS_INDEX_15V].gpio, gpios[GPIOS_INDEX_15V].pin, GPIO_PIN_RESET);
		set_rail_monitor_enable(RAIL_15v, DISABLED);
		break;
	}

	case CMD_N200V_ON:
	{
		HAL_GPIO_WritePin(gpios[GPIOS_INDEX_N200V].gpio, gpios[GPIOS_INDEX_N200V].pin, GPIO_PIN_SET);
		set_rail_monitor_enable(RAIL_n200v, ENABLED);
		break;
	}

	case CMD_N200V_OFF:
	{
		HAL_GPIO_WritePin(gpios[GPIOS_INDEX_N200V].gpio, gpios[GPIOS_INDEX_N200V].pin, GPIO_PIN_RESET);
		set_rail_monitor_enable(RAIL_n200v, DISABLED);
		break;
	}

	case CMD_N800V_ON:
	{
		HAL_GPIO_WritePin(gpios[GPIOS_INDEX_N800V].gpio, gpios[GPIOS_INDEX_N800V].pin, GPIO_PIN_SET);
		set_rail_monitor_enable(RAIL_n800v, ENABLED);
		break;
	}

	case CMD_N800V_OFF:
	{
		HAL_GPIO_WritePin(gpios[GPIOS_INDEX_N800V].gpio, gpios[GPIOS_INDEX_N800V].pin, GPIO_PIN_RESET);
		set_rail_monitor_enable(RAIL_n800v, DISABLED);
		break;
	}

	case CMD_AUTOSWEEP_ON:
	{
		HAL_DAC_Start_DMA(&hdac1, DAC_CHANNEL_1, DAC_OUT, DAC_OUT_ARRAY_SIZE, DAC_ALIGN_12B_R);
		break;
	}

	case CMD_AUTOSWEEP_OFF:
	{
		HAL_DAC_Stop_DMA(&hdac1, DAC_CHANNEL_1);
		break;
	}

	case CMD_ERPA_ON:
	{
		osEventFlagsSet(packet_event_flags, ERPA_FLAG);
		TIM2->CCR4 = ERPA_PWM_FREQ;
		ERPA_ENABLED = ENABLED;
		break;
	}

	case CMD_ERPA_OFF:
	{
		ERPA_ENABLED = DISABLED;
		TIM2->CCR4 = 0;
		break;
	}

	case CMD_PMT_ON:
	{
		HAL_TIM_OC_Start_IT(&htim1, TIM_CHANNEL_1);
		osEventFlagsSet(packet_event_flags, PMT_FLAG);
		break;
	}

	case CMD_PMT_OFF:
	{
		HAL_TIM_OC_Stop_IT(&htim1, TIM_CHANNEL_1);
		break;
	}

	case CMD_HK_ON:
	{
		osEventFlagsSet(packet_event_flags, HK_FLAG);
		HK_ENABLED = ENABLED;
		break;
	}

	case CMD_HK_OFF:
	{
		HK_ENABLED = DISABLED;
		break;
	}

	case CMD_STEP_UP:
	{
		if (step < 14)
		{
			step += 2;
			HAL_DAC_SetValue(&hdac1, DAC_CHANNEL_1, DAC_ALIGN_12B_R,
					DAC_OUT[step]);
			HAL_DAC_Start(&hdac1, DAC_CHANNEL_1);
		}
		break;
	}

	case CMD_STEP_DOWN:
	{
		if (step > 1)
		{
			step -= 2;
			HAL_DAC_SetValue(&hdac1, DAC_CHANNEL_1, DAC_ALIGN_12B_R,
					DAC_OUT[step]);
			HAL_DAC_Start(&hdac1, DAC_CHANNEL_1);
		}
		break;
	}

	case CMD_FACTOR_UP:
	{
		if (cadence <= 50000)
		{
			cadence *= 2;
			TIM2->ARR = cadence;
		}
		break;
	}

	case CMD_FACTOR_DOWN:
	{
		if (cadence >= 6250)
		{
			cadence /= 2;
			TIM2->ARR = cadence;
		}
		break;
	}

	case CMD_ENTER_STOP:
	{
		osEventFlagsSet(utility_event_flags, STOP_FLAG);
		break;
	}

	case CMD_AUTO_INIT:
	{
		osEventFlagsSet(utility_event_flags, AUTOINIT_FLAG);
		break;
	}

	case CMD_AUTO_DEINIT:
	{
		osEventFlagsSet(utility_event_flags, AUTODEINIT_FLAG);
		break;
	}

	case CMD_SYNC_MODE:
	{
		osEventFlagsSet(mode_event_flags, SYNC_FLAG);
		break;
	}

	case CMD_SCIENCE_MODE:
	{
		osEventFlagsSet(mode_event_flags, SCIENCE_FLAG);
		break;
	}

	case CMD_IDLE_MODE:
	{
		osEventFlagsSet(mode_event_flags, IDLE_FLAG);
		break;
	}

	case CMD_RESET_ERROR_COUNTERS:
	{
		reset_error_counters();
		break;
	}

	case CMD_SEND_PREVIOUS_ERROR:
	{
#ifdef ERROR_HANDLING_ENABLED
		send_previous_error_packet();
#endif
		break;
	}

	case CMD_SEND_VERSION_PACKET:
	{
		create_version_packet();
		break;
	}

	case CMD_SEND_VERSION_INFO:
	{
		// Ensure the GIT_INFO macro is defined
		#ifdef GIT_COMMIT_HASH
			// Transmit the version information via UART
			HAL_UART_Transmit(&huart1, (uint8_t*)GIT_INFO, strlen(GIT_INFO), HAL_MAX_DELAY);
		#else
			// Transmit a fallback message if version information is unavailable
			const char* fallback_message = "Version information unavailable.\r\n";
			HAL_UART_Transmit(&huart1, (uint8_t*)fallback_message, strlen(fallback_message), HAL_MAX_DELAY);
		#endif
		break;
	}

	case CMD_UPDATE_FIRMWARE:
	{
		uint8_t msg = 0x79;
		HAL_UART_Transmit(&huart1, &msg, 1, 1000);
		SetBootloaderFlag();
		break;
	}

	case CMD_ST_BL_SYNC:
	{
	    uint8_t ack = 0x79;
	    HAL_UART_Transmit(&huart1, &ack, 1, 1000);
	    break;
	}

	default:
	{
		// Unknown command
		break;
	}
	}
}

/**
 * @brief Retrieves and handles the cause of a system reset.
 *        Checks for watchdog and brownout reset conditions and reports errors.
 */
ERROR_STRUCT get_reset_cause()
{
	ERROR_STRUCT error;
	error.category = EC_UNDEFINED;
	error.detail = ED_UNDEFINED;

	if (__HAL_RCC_GET_FLAG(RCC_FLAG_IWDG1RST))
    {
        error.category = EC_watchdog;
        error.detail = ED_UNDEFINED;
        __HAL_RCC_CLEAR_RESET_FLAGS();
        increment_error_counter(error);
        set_previous_error(error);
    }

    else if (__HAL_RCC_GET_FLAG(RCC_FLAG_BORRST))
    {
        error.category = EC_brownout;
        error.detail = ED_UNDEFINED;
        __HAL_RCC_CLEAR_RESET_FLAGS();
        increment_error_counter(error);
        set_previous_error(error);
    }

	return error;
}

/* USER CODE END 0 */

int main(void)
{
  /* USER CODE BEGIN 1 */
	JumpToBootloader();
  /* USER CODE END 1 */

  /* MCU Configuration--------------------------------------------------------*/

  /* Reset of all peripherals, Initializes the Flash interface and the Systick. */
  HAL_Init();

  /* Configure the system clock */
  SystemClock_Config();

/* Configure the peripherals common clocks */
  PeriphCommonClock_Config();

  /* Initialize all configured peripherals */
  MX_GPIO_Init();
  MX_DMA_Init();
  MX_USART1_UART_Init();
  MX_I2C1_Init();
  MX_SPI2_Init();
  MX_TIM2_Init();
  MX_TIM1_Init();
  MX_ADC3_Init();
  MX_ADC1_Init();
  MX_DAC1_Init();
  MX_SPI1_Init();
  MX_RTC_Init();
  MX_IWDG1_Init();
  MX_RAMECC_Init();
  MX_TIM3_Init();
  /* USER CODE BEGIN 2 */
  system_setup();
  /* USER CODE END 2 */

  /* Init scheduler */
  osKernelInitialize();  /* Call init function for freertos objects (in freertos.c) */
  MX_FREERTOS_Init();

  /* Start scheduler */
  osKernelStart();
  /* We should never get here as control is now taken by the scheduler */
  /* Infinite loop */
	while (1)
	{

	}
}

void SystemClock_Config(void)
{
  RCC_OscInitTypeDef RCC_OscInitStruct = {0};
  RCC_ClkInitTypeDef RCC_ClkInitStruct = {0};

  /** Supply configuration update enable
  */
  HAL_PWREx_ConfigSupply(PWR_LDO_SUPPLY);

  /** Configure the main internal regulator output voltage
  */
  __HAL_PWR_VOLTAGESCALING_CONFIG(PWR_REGULATOR_VOLTAGE_SCALE3);

  while(!__HAL_PWR_GET_FLAG(PWR_FLAG_VOSRDY)) {}

  /** Initializes the RCC Oscillators according to the specified parameters
  * in the RCC_OscInitTypeDef structure.
  */
  RCC_OscInitStruct.OscillatorType = RCC_OSCILLATORTYPE_HSI|RCC_OSCILLATORTYPE_LSI
                              |RCC_OSCILLATORTYPE_HSE;
  RCC_OscInitStruct.HSEState = RCC_HSE_ON;
  RCC_OscInitStruct.HSIState = RCC_HSI_DIV2;
  RCC_OscInitStruct.HSICalibrationValue = RCC_HSICALIBRATION_DEFAULT;
  RCC_OscInitStruct.LSIState = RCC_LSI_ON;
  RCC_OscInitStruct.PLL.PLLState = RCC_PLL_ON;
  RCC_OscInitStruct.PLL.PLLSource = RCC_PLLSOURCE_HSE;
  RCC_OscInitStruct.PLL.PLLM = 4;
  RCC_OscInitStruct.PLL.PLLN = 24;
  RCC_OscInitStruct.PLL.PLLP = 2;
  RCC_OscInitStruct.PLL.PLLQ = 2;
  RCC_OscInitStruct.PLL.PLLR = 2;
  RCC_OscInitStruct.PLL.PLLRGE = RCC_PLL1VCIRANGE_2;
  RCC_OscInitStruct.PLL.PLLVCOSEL = RCC_PLL1VCOMEDIUM;
  RCC_OscInitStruct.PLL.PLLFRACN = 0;
  if (HAL_RCC_OscConfig(&RCC_OscInitStruct) != HAL_OK)
  {
    Error_Handler();
  }

  /** Initializes the CPU, AHB and APB buses clocks
  */
  RCC_ClkInitStruct.ClockType = RCC_CLOCKTYPE_HCLK|RCC_CLOCKTYPE_SYSCLK
                              |RCC_CLOCKTYPE_PCLK1|RCC_CLOCKTYPE_PCLK2
                              |RCC_CLOCKTYPE_D3PCLK1|RCC_CLOCKTYPE_D1PCLK1;
  RCC_ClkInitStruct.SYSCLKSource = RCC_SYSCLKSOURCE_PLLCLK;
  RCC_ClkInitStruct.SYSCLKDivider = RCC_SYSCLK_DIV1;
  RCC_ClkInitStruct.AHBCLKDivider = RCC_HCLK_DIV1;
  RCC_ClkInitStruct.APB3CLKDivider = RCC_APB3_DIV1;
  RCC_ClkInitStruct.APB1CLKDivider = RCC_APB1_DIV2;
  RCC_ClkInitStruct.APB2CLKDivider = RCC_APB2_DIV1;
  RCC_ClkInitStruct.APB4CLKDivider = RCC_APB4_DIV1;

  if (HAL_RCC_ClockConfig(&RCC_ClkInitStruct, FLASH_LATENCY_1) != HAL_OK)
  {
    Error_Handler();
  }
}

void PeriphCommonClock_Config(void)
{
  RCC_PeriphCLKInitTypeDef PeriphClkInitStruct = {0};

  /** Initializes the peripherals clock
  */
  PeriphClkInitStruct.PeriphClockSelection = RCC_PERIPHCLK_ADC;
  PeriphClkInitStruct.PLL2.PLL2M = 4;
  PeriphClkInitStruct.PLL2.PLL2N = 24;
  PeriphClkInitStruct.PLL2.PLL2P = 8;
  PeriphClkInitStruct.PLL2.PLL2Q = 2;
  PeriphClkInitStruct.PLL2.PLL2R = 2;
  PeriphClkInitStruct.PLL2.PLL2RGE = RCC_PLL2VCIRANGE_2;
  PeriphClkInitStruct.PLL2.PLL2VCOSEL = RCC_PLL2VCOMEDIUM;
  PeriphClkInitStruct.PLL2.PLL2FRACN = 0;
  PeriphClkInitStruct.AdcClockSelection = RCC_ADCCLKSOURCE_PLL2;
  if (HAL_RCCEx_PeriphCLKConfig(&PeriphClkInitStruct) != HAL_OK)
  {
    Error_Handler();
  }
}

/* USER CODE BEGIN 4 */

/**
 * @brief Initializes the system and its components.
 *        Sets up error handling, event flags, timer, voltage monitoring, ADC, and UART reception.
 */
void system_setup()
{
#ifdef ERROR_HANDLING_ENABLED
	error_counter_init();
	init_flash_ecc();
#endif

	packet_event_flags = osEventFlagsNew(NULL);
    if (packet_event_flags == NULL)
    {
        Error_Handler();
    }

    utility_event_flags = osEventFlagsNew(NULL);
    if (utility_event_flags == NULL)
    {
        Error_Handler();
    }

    mode_event_flags = osEventFlagsNew(NULL);
    if (mode_event_flags == NULL)
    {
        Error_Handler();
    }

    TIM2->CCR4 = 0;
	HAL_TIM_OC_Start_IT(&htim2, TIM_CHANNEL_4);

	voltage_monitor_init();

	init_adc_dma();

	HAL_UART_Receive_IT(&huart1, UART_RX_BUFFER, 1);
}

/**
 * @brief Sends an acknowledgment (ACK) over UART.
 *        Transmits a single byte indicating a successful operation.
 */
void send_ACK()
{
	static uint8_t tx_buffer[1];

	tx_buffer[0] = ACK;
	HAL_UART_Transmit(&huart1, tx_buffer, 1, UART_TIMEOUT_MS);
}

/**
 * @brief Sends a negative acknowledgment (NACK) over UART.
 *        Transmits a single byte indicating an unsuccessful operation.
 */
void send_NACK()
{
	static uint8_t tx_buffer[1];

	tx_buffer[0] = NACK;
	HAL_UART_Transmit(&huart1, tx_buffer, 1, UART_TIMEOUT_MS);
}

/**
 * @brief Retrieves the current step value based on the DAC output.
 *
 * @return The corresponding step value based on the DAC1 output, or -1 if out of range.
 */
STEP_VALUES get_current_step()
{
	int dac_value;

	dac_value = DAC1->DHR12R1;

	switch (dac_value)
	{
	case DAC_VALUE_0:
		return STEP_0;

	case DAC_VALUE_620:
		return STEP_1;

	case DAC_VALUE_1241:
		return STEP_2;

	case DAC_VALUE_1861:
		return STEP_3;

	case DAC_VALUE_2482:
		return STEP_4;

	case DAC_VALUE_3103:
		return STEP_5;

	case DAC_VALUE_3723:
		return STEP_6;

	case DAC_VALUE_4095:
		return STEP_7;

	default:
		return INVALID_STEP;
	}
}

/**
 * @brief Enters low-power stop mode after sending an acknowledgment.
 *        Suspends all FreeRTOS tasks, enters stop mode, and resumes configuration upon wake-up.
 */
void enter_stop()
{
	  send_ACK();

	  vTaskSuspendAll();
	  HAL_PWR_EnterSTOPMode(PWR_LOWPOWERREGULATOR_ON, PWR_STOPENTRY_WFI);

	  // MCU resumes here after waking from stop mode.

	  NVIC_SystemReset();
	  SystemClock_Config();
	  reset_packet_sequence_numbers();
	  xTaskResumeAll();
}

/**
 * @brief Initializes Flash ECC (Error Correction Code) settings.
 *        Unlocks Flash memory, sets IRQ priority, and enables ECC correction and detection interrupts.
 */
void init_flash_ecc()
{
	HAL_FLASH_Unlock();

	HAL_NVIC_SetPriority(FLASH_IRQn, 15, 0);
	HAL_NVIC_EnableIRQ(FLASH_IRQn);
	HAL_FLASHEx_EnableEccCorrectionInterrupt();
	HAL_FLASHEx_EnableEccDetectionInterrupt();
}

/* USER CODE END 4 */

void HAL_TIM_PeriodElapsedCallback(TIM_HandleTypeDef *htim)
{
  /* USER CODE BEGIN Callback 0 */
	HAL_IWDG_Refresh(&hiwdg1);

  /* USER CODE END Callback 0 */
  if (htim->Instance == TIM6) {
    HAL_IncTick();
  }
  /* USER CODE BEGIN Callback 1 */
  if (htim == &htim3)
  {
	NVIC_SystemReset();
  }
  /* USER CODE END Callback 1 */
}

void Error_Handler(void)
{
  /* USER CODE BEGIN Error_Handler_Debug */
	/* User can add his own implementation to report the HAL error return state */
	ERROR_STRUCT error;
	error.category = EC_peripheral;
	error.detail = ED_UNDEFINED;
	handle_error(error);
  /* USER CODE END Error_Handler_Debug */
}

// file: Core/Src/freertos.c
/* USER CODE BEGIN Header */
/**
 ******************************************************************************
 * @file           : freertos.c
 * @author 		   : Jared Morrison
 * @date	 	   : October 9, 2024
 * @brief          : Implementation of freertos tasks.
 ******************************************************************************
 * @attention
 *
 * Copyright (c) 2024 STMicroelectronics.
 * All rights reserved.
 *
 * This software is licensed under terms that can be found in the LICENSE file
 * in the root directory of this software component.
 * If no LICENSE file comes with this software, it is provided AS-IS.
 *
 ******************************************************************************
 */
/* USER CODE END Header */

#include "FreeRTOS.h"
#include "task.h"
#include "main.h"
#include "cmsis_os.h"

/* USER CODE BEGIN Includes */
#include "usart.h"
#include "voltage_monitor.h"
#include "packet_creation.h"
#include "dac.h"
#include "tim.h"
#include "iwdg.h"
#include <stdbool.h>
/* USER CODE END Includes */

typedef StaticTask_t osStaticThreadDef_t;

/* USER CODE BEGIN PD */
#define PS_RAIL_DELAY 100
#define IDLE_TO_SCIENCE_DELAY 1000
#define IDLE_TO_VOLTAGE_MONITOR_DELAY 3500	// TODO: Reduce to 1000 for assembled instrument
#define SYNC_DELAY 10
/* USER CODE END PD */

/* Definitions for PMT_task */
osThreadId_t PMT_taskHandle;
uint32_t PMT_taskBuffer[ 128 ];
osStaticThreadDef_t PMT_taskControlBlock;
const osThreadAttr_t PMT_task_attributes = {
  .name = "PMT_task",
  .cb_mem = &PMT_taskControlBlock,
  .cb_size = sizeof(PMT_taskControlBlock),
  .stack_mem = &PMT_taskBuffer[0],
  .stack_size = sizeof(PMT_taskBuffer),
  .priority = (osPriority_t) osPriorityRealtime6,
};
/* Definitions for ERPA_task */
osThreadId_t ERPA_taskHandle;
uint32_t ERPA_taskBuffer[ 128 ];
osStaticThreadDef_t ERPA_taskControlBlock;
const osThreadAttr_t ERPA_task_attributes = {
  .name = "ERPA_task",
  .cb_mem = &ERPA_taskControlBlock,
  .cb_size = sizeof(ERPA_taskControlBlock),
  .stack_mem = &ERPA_taskBuffer[0],
  .stack_size = sizeof(ERPA_taskBuffer),
  .priority = (osPriority_t) osPriorityRealtime7,
};
/* Definitions for HK_task */
osThreadId_t HK_taskHandle;
uint32_t HK_taskBuffer[ 128 ];
osStaticThreadDef_t HK_taskControlBlock;
const osThreadAttr_t HK_task_attributes = {
  .name = "HK_task",
  .cb_mem = &HK_taskControlBlock,
  .cb_size = sizeof(HK_taskControlBlock),
  .stack_mem = &HK_taskBuffer[0],
  .stack_size = sizeof(HK_taskBuffer),
  .priority = (osPriority_t) osPriorityRealtime4,
};
/* Definitions for AUTOINIT_task */
osThreadId_t AUTOINIT_taskHandle;
uint32_t AUTOINIT_taskBuffer[ 128 ];
osStaticThreadDef_t AUTOINIT_taskControlBlock;
const osThreadAttr_t AUTOINIT_task_attributes = {
  .name = "AUTOINIT_task",
  .cb_mem = &AUTOINIT_taskControlBlock,
  .cb_size = sizeof(AUTOINIT_taskControlBlock),
  .stack_mem = &AUTOINIT_taskBuffer[0],
  .stack_size = sizeof(AUTOINIT_taskBuffer),
  .priority = (osPriority_t) osPriorityNormal,
};
/* Definitions for AUTODEINIT_task */
osThreadId_t AUTODEINIT_taskHandle;
uint32_t AUTODEINIT_taskBuffer[ 128 ];
osStaticThreadDef_t AUTODEINIT_taskControlBlock;
const osThreadAttr_t AUTODEINIT_task_attributes = {
  .name = "AUTODEINIT_task",
  .cb_mem = &AUTODEINIT_taskControlBlock,
  .cb_size = sizeof(AUTODEINIT_taskControlBlock),
  .stack_mem = &AUTODEINIT_taskBuffer[0],
  .stack_size = sizeof(AUTODEINIT_taskBuffer),
  .priority = (osPriority_t) osPriorityNormal,
};
/* Definitions for Voltage_Monitor */
osThreadId_t Voltage_MonitorHandle;
uint32_t Voltage_MonitorBuffer[ 128 ];
osStaticThreadDef_t Voltage_MonitorControlBlock;
const osThreadAttr_t Voltage_Monitor_attributes = {
  .name = "Voltage_Monitor",
  .cb_mem = &Voltage_MonitorControlBlock,
  .cb_size = sizeof(Voltage_MonitorControlBlock),
  .stack_mem = &Voltage_MonitorBuffer[0],
  .stack_size = sizeof(Voltage_MonitorBuffer),
  .priority = (osPriority_t) osPriorityRealtime5,
};
/* Definitions for STOP_task */
osThreadId_t STOP_taskHandle;
uint32_t STOP_taskBuffer[ 128 ];
osStaticThreadDef_t STOP_taskControlBlock;
const osThreadAttr_t STOP_task_attributes = {
  .name = "STOP_task",
  .cb_mem = &STOP_taskControlBlock,
  .cb_size = sizeof(STOP_taskControlBlock),
  .stack_mem = &STOP_taskBuffer[0],
  .stack_size = sizeof(STOP_taskBuffer),
  .priority = (osPriority_t) osPriorityNormal,
};
/* Definitions for Science_task */
osThreadId_t Science_taskHandle;
uint32_t Science_taskBuffer[ 128 ];
osStaticThreadDef_t Science_taskControlBlock;
const osThreadAttr_t Science_task_attributes = {
  .name = "Science_task",
  .cb_mem = &Science_taskControlBlock,
  .cb_size = sizeof(Science_taskControlBlock),
  .stack_mem = &Science_taskBuffer[0],
  .stack_size = sizeof(Science_taskBuffer),
  .priority = (osPriority_t) osPriorityRealtime7,
};
/* Definitions for Idle_task */
osThreadId_t Idle_taskHandle;
uint32_t Idle_taskBuffer[ 128 ];
osStaticThreadDef_t Idle_taskControlBlock;
const osThreadAttr_t Idle_task_attributes = {
  .name = "Idle_task",
  .cb_mem = &Idle_taskControlBlock,
  .cb_size = sizeof(Idle_taskControlBlock),
  .stack_mem = &Idle_taskBuffer[0],
  .stack_size = sizeof(Idle_taskBuffer),
  .priority = (osPriority_t) osPriorityRealtime7,
};
/* Definitions for Sync_task */
osThreadId_t Sync_taskHandle;
uint32_t Sync_taskBuffer[ 128 ];
osStaticThreadDef_t Sync_taskControlBlock;
const osThreadAttr_t Sync_task_attributes = {
  .name = "Sync_task",
  .cb_mem = &Sync_taskControlBlock,
  .cb_size = sizeof(Sync_taskControlBlock),
  .stack_mem = &Sync_taskBuffer[0],
  .stack_size = sizeof(Sync_taskBuffer),
  .priority = (osPriority_t) osPriorityNormal,
};

void PMT_init(void *argument);
void ERPA_init(void *argument);
void HK_init(void *argument);
void AUTOINIT_init(void *argument);
void AUTODEINIT_init(void *argument);
void Voltage_Monitor_init(void *argument);
void STOP_init(void *argument);
void Science_init(void *argument);
void Idle_init(void *argument);
void Sync_init(void *argument);

void MX_FREERTOS_Init(void); /* (MISRA C 2004 rule 8.1) */

/* Hook prototypes */
void vApplicationTickHook(void);
void vApplicationStackOverflowHook(xTaskHandle xTask, signed char *pcTaskName);

/* USER CODE BEGIN 3 */
/**
 * @brief Tick hook function called by each tick interrupt.
 *		  Increments uptime_millis, used in time tagging.
 */
void vApplicationTickHook( void )
{
   /* This function will be called by each tick interrupt if
   configUSE_TICK_HOOK is set to 1 in FreeRTOSConfig.h. User code can be
   added here, but the tick hook is called from an interrupt context, so
   code must not attempt to block, and only the interrupt safe FreeRTOS API
   functions can be used (those that end in FromISR()). */
	uptime_millis++;

}
/* USER CODE END 3 */

/* USER CODE BEGIN 4 */
void vApplicationStackOverflowHook(xTaskHandle xTask, signed char *pcTaskName)
{
   /* Run time stack overflow checking is performed if
   configCHECK_FOR_STACK_OVERFLOW is defined to 1 or 2. This hook function is
   called if a stack overflow is detected. */
}
/* USER CODE END 4 */

void MX_FREERTOS_Init(void) {

  /* Create the thread(s) */
  /* creation of PMT_task */
  PMT_taskHandle = osThreadNew(PMT_init, NULL, &PMT_task_attributes);

  /* creation of ERPA_task */
  ERPA_taskHandle = osThreadNew(ERPA_init, NULL, &ERPA_task_attributes);

  /* creation of HK_task */
  HK_taskHandle = osThreadNew(HK_init, NULL, &HK_task_attributes);

  /* creation of AUTOINIT_task */
  AUTOINIT_taskHandle = osThreadNew(AUTOINIT_init, NULL, &AUTOINIT_task_attributes);

  /* creation of AUTODEINIT_task */
  AUTODEINIT_taskHandle = osThreadNew(AUTODEINIT_init, NULL, &AUTODEINIT_task_attributes);

  /* creation of Voltage_Monitor */
  Voltage_MonitorHandle = osThreadNew(Voltage_Monitor_init, NULL, &Voltage_Monitor_attributes);

  /* creation of STOP_task */
  STOP_taskHandle = osThreadNew(STOP_init, NULL, &STOP_task_attributes);

  /* creation of Science_task */
  Science_taskHandle = osThreadNew(Science_init, NULL, &Science_task_attributes);

  /* creation of Idle_task */
  Idle_taskHandle = osThreadNew(Idle_init, NULL, &Idle_task_attributes);

  /* creation of Sync_task */
  Sync_taskHandle = osThreadNew(Sync_init, NULL, &Sync_task_attributes);

}

/* USER CODE BEGIN Header_PMT_init */
/**
 * @brief Initializes the PMT thread.
 *
 * This function waits for PMT event flags, creates a PMT packet,
 * and yields control to other threads in an infinite loop.
 */
/* USER CODE END Header_PMT_init */
void PMT_init(void *argument)
{
  /* USER CODE BEGIN PMT_init */
  /* Infinite loop */
	for (;;)
	{
		osEventFlagsWait(packet_event_flags, PMT_FLAG, osFlagsWaitAny, osWaitForever);

		create_pmt_packet();

		osThreadYield();
	}
  /* USER CODE END PMT_init */
}

/* USER CODE BEGIN Header_ERPA_init */
/**
 * @brief Initializes the ERPA thread.
 *
 * This function waits for ERPA event flags, creates an ERPA packet,
 * and yields control to other threads in an infinite loop.
 */
/* USER CODE END Header_ERPA_init */
void ERPA_init(void *argument)
{
  /* USER CODE BEGIN ERPA_init */
  /* Infinite loop */
	for (;;)
	{
		osEventFlagsWait(packet_event_flags, ERPA_FLAG, osFlagsWaitAny, osWaitForever);

		create_erpa_packet();

		osThreadYield();
	}
  /* USER CODE END ERPA_init */
}

/* USER CODE BEGIN Header_HK_init */
/**
 * @brief Initializes the HK thread.
 *
 * This function waits for HK event flags, creates an HK packet,
 * and yields control to other threads in an infinite loop.
 */
/* USER CODE END Header_HK_init */
void HK_init(void *argument)
{
  /* USER CODE BEGIN HK_init */
  /* Infinite loop */
	for (;;)
	{
		osEventFlagsWait(packet_event_flags, HK_FLAG, osFlagsWaitAny, osWaitForever);

		create_hk_packet();

		osThreadYield();
	}
  /* USER CODE END HK_init */
}

/* USER CODE BEGIN Header_AUTOINIT_init */
/**
 * @brief Initializes the AUTOINIT thread.
 *
 * This function waits for AUTOINIT event flags, enables all voltages
 * from SDN1 to 15V, updates the rail monitor, and yields control to
 * other threads in an infinite loop.
 */
/* USER CODE END Header_AUTOINIT_init */
void AUTOINIT_init(void *argument)
{
  /* USER CODE BEGIN AUTOINIT_init */
  /* Infinite loop */
	for (;;)
	{
		osEventFlagsWait(utility_event_flags, AUTOINIT_FLAG, osFlagsWaitAny, osWaitForever);

		// Enabling all voltages from SDN1 to 15V (inclusive)
		for (int i = GPIOS_INDEX_SDN1; i <= GPIOS_INDEX_15V; i++)
		{
			HAL_GPIO_WritePin(gpios[i].gpio, gpios[i].pin, GPIO_PIN_SET);
			osDelay(PS_RAIL_DELAY);
		}

		// Telling rail monitor which rails are now enabled
		for (int i = RAIL_2v5; i <= RAIL_15v; i++)
		{
			set_rail_monitor_enable(i, ENABLED);
		}
		osThreadYield();
	}
  /* USER CODE END AUTOINIT_init */
}

/* USER CODE BEGIN Header_AUTODEINIT_init */
/**
 * @brief Initializes the AUTODEINIT thread.
 *
 * This function waits for AUTODEINIT event flags, disables all voltages
 * from 15V to SDN1, updates the rail monitor, and yields control to
 * other threads in an infinite loop.
 */
/* USER CODE END Header_AUTODEINIT_init */
void AUTODEINIT_init(void *argument)
{
  /* USER CODE BEGIN AUTODEINIT_init */
  /* Infinite loop */
	for (;;)
	{
		osEventFlagsWait(utility_event_flags, AUTODEINIT_FLAG, osFlagsWaitAny, osWaitForever);

		// Telling rail monitor which rails are now disabled
		for (int i = RAIL_15v; i >= RAIL_2v5; i--)
		{
			set_rail_monitor_enable(i, DISABLED);
		}

		// Disabling all voltages from 15V to SDN1 (inclusive)
		for (int i = GPIOS_INDEX_15V; i >= GPIOS_INDEX_SDN1; i--)
		{
			HAL_GPIO_WritePin(gpios[i].gpio, gpios[i].pin, GPIO_PIN_RESET);
			osDelay(PS_RAIL_DELAY);
		}

		osThreadYield();
	}
  /* USER CODE END AUTODEINIT_init */
}

/* USER CODE BEGIN Header_Voltage_Monitor_init */
/**
 * @brief Initializes the Voltage Monitor thread.
 *
 * This function waits for voltage monitor event flags, sets the rail monitor,
 * and checks rail status. If rails are out of bounds, it transitions to idle mode
 * before returning to science mode.
 */
/* USER CODE END Header_Voltage_Monitor_init */
void Voltage_Monitor_init(void *argument)
{
  /* USER CODE BEGIN Voltage_Monitor_init */
	uint8_t rails_in_bound = 1;
  /* Infinite loop */
  for(;;)
  {
	  osEventFlagsWait(utility_event_flags, VOLTAGE_MONITOR_FLAG, osFlagsWaitAny, osWaitForever);
	  set_rail_monitor();
#ifdef ERROR_HANDLING_ENABLED
	  rails_in_bound = monitor_rails();
	  if (!rails_in_bound && !IDLING)
	  {
		  osEventFlagsSet(mode_event_flags, IDLE_FLAG);
		  while (!IDLING) {};
		  osDelay(IDLE_TO_SCIENCE_DELAY);
		  osEventFlagsSet(mode_event_flags, SCIENCE_FLAG);
	  }
#endif
  }
  /* USER CODE END Voltage_Monitor_init */
}

/* USER CODE BEGIN Header_STOP_init */
/**
 * @brief Initializes the STOP thread.
 *
 * This function waits for the STOP event flag, clears it, sets the IDLE flag,
 * and enters stop mode when idle.
 */
/* USER CODE END Header_STOP_init */
void STOP_init(void *argument)
{
  /* USER CODE BEGIN STOP_init */
  /* Infinite loop */
  for(;;)
  {
	  osEventFlagsWait(utility_event_flags, STOP_FLAG, osFlagsWaitAny,osWaitForever);
	  osEventFlagsClear(utility_event_flags, STOP_FLAG);

	  osEventFlagsSet(mode_event_flags, IDLE_FLAG);
	  while (!IDLING) {};

	  enter_stop();
  }
  /* USER CODE END STOP_init */
}

/* USER CODE BEGIN Header_Science_init */
/**
 * @brief Initializes the Science thread.
 *
 * This function waits for the SCIENCE event flag, enables all voltages,
 * updates the rail monitor, starts DAC in DMA mode, and resets packet
 * sequence numbers, transitioning to the science mode.
 */
/* USER CODE END Header_Science_init */
void Science_init(void *argument)
{
  /* USER CODE BEGIN Science_init */

	/* Infinite loop */
  for(;;)
  {
		osEventFlagsWait(mode_event_flags, SCIENCE_FLAG, osFlagsWaitAny, osWaitForever);
		// === TEMP CHECK BEFORE HARDWARE INIT ===
		const uint16_t ENTRY_TEMP_LIMIT_RAW = 720; // 45°C × 16
		bool temp_ok = true;
		VOLTAGE_RAIL* rails = get_rail_monitor();

		for (int i = RAIL_TEMP1; i <= RAIL_TEMP4; i++) {
		    if (rails[i].data >= ENTRY_TEMP_LIMIT_RAW) {
		        temp_ok = false;

		        // Increment and track OOB
		        rails[i].error_count++;
		        switch (rails[i].error_count) {
		            case 1:
		                rails[i].OOB_1 = rails[i].data;
		                break;
		            case 2:
		                rails[i].OOB_2 = rails[i].data;
		                break;
		            case 3:
		            {
		                rails[i].OOB_3 = rails[i].data;

		                ERROR_STRUCT error;
		                error.detail = get_rail_name_error_detail(rails[i].name);
		                error.category = EC_power_supply_rail;
		                error.OOB_1 = rails[i].OOB_1;
		                error.OOB_2 = rails[i].OOB_2;
		                error.OOB_3 = rails[i].OOB_3;
		                handle_error(error);
		                break;
		            }
		            default:
		                break;
		        }
		    }
		}

		if (!temp_ok)
		{
			// Abort Science mode entry
			IDLING = 1;  // Mark system idle again

			// Forcefully switch back to IDLE mode
			osEventFlagsSet(mode_event_flags, IDLE_FLAG);

			// Prevent proceeding with science init
			osThreadYield();  // Allow other threads to take over
			continue;
		}
		osThreadSuspend(Voltage_MonitorHandle);
		IDLING = 0;

		// Enabling all voltages
		for (int i = GPIOS_INDEX_SDN1; i <= GPIOS_INDEX_N800V; i++)
		{
			HAL_GPIO_WritePin(gpios[i].gpio, gpios[i].pin, GPIO_PIN_SET);
			osDelay(PS_RAIL_DELAY);
		}

		// Telling rail monitor which voltages are now enabled
		for (int i = RAIL_busvmon; i <= RAIL_TMP1; i++)
		{
			set_rail_monitor_enable(i, ENABLED);
		}
		osThreadResume(Voltage_MonitorHandle);

		__disable_irq();
		HAL_DAC_Start_DMA(&hdac1, DAC_CHANNEL_1, DAC_OUT, DAC_OUT_ARRAY_SIZE, DAC_ALIGN_12B_R);
		HK_ENABLED = ENABLED;
		ERPA_ENABLED = ENABLED;
		uptime_millis = 0;

		reset_packet_sequence_numbers();
		//osEventFlagsSet(packet_event_flags, HK_FLAG);
		TIM2->CCR4 = ERPA_PWM_FREQ;
		HAL_TIM_OC_Start_IT(&htim1, TIM_CHANNEL_1);
		__enable_irq();

		osThreadYield();
  }
  /* USER CODE END Science_init */
}

/* USER CODE BEGIN Header_Idle_init */
/**
 * @brief Initializes the Idle thread.
 *
 * This function waits for the IDLE event flag, disables ERPA and HK,
 * stops the DAC, updates the rail monitor, disables all voltages,
 * and yields control to other threads.
 */
/* USER CODE END Header_Idle_init */
void Idle_init(void *argument)
{
  /* USER CODE BEGIN Idle_init */

  /* Infinite loop */
  for(;;)
  {
		osEventFlagsWait(mode_event_flags, IDLE_FLAG, osFlagsWaitAny, osWaitForever);

		ERPA_ENABLED = DISABLED;
		TIM2->CCR4 = 0;
		HAL_TIM_OC_Stop_IT(&htim1, TIM_CHANNEL_1);
		HK_ENABLED = DISABLED;
		HAL_DAC_Stop_DMA(&hdac1, DAC_CHANNEL_1);
		osThreadSuspend(Voltage_MonitorHandle);

		// Telling rail monitor which voltages are now disabled
		for (int i = RAIL_TMP1; i >= RAIL_busvmon; i--)
		{
			set_rail_monitor_enable(i, DISABLED);
		}

		// Disabling all voltages
		for (int i = GPIOS_INDEX_N800V; i >= GPIOS_INDEX_SDN1; i--)
		{
			HAL_GPIO_WritePin(gpios[i].gpio, gpios[i].pin, GPIO_PIN_RESET);
			osDelay(PS_RAIL_DELAY);
		}
		osDelay(IDLE_TO_VOLTAGE_MONITOR_DELAY);
		IDLING = 1;
		osThreadResume(Voltage_MonitorHandle);

		// Yield thread control
		osThreadYield();
  }
  /* USER CODE END Idle_init */
}

/* USER CODE BEGIN Header_Sync_init */
/**
 * @brief Initializes the Sync thread.
 *
 * This function waits for the SYNC event flag, sends an acknowledgment,
 * waits for a specific key value to be received, calibrates the RTC,
 * and handles UART communication for error counting and reset cause.
 */
/* USER CODE END Header_Sync_init */
void Sync_init(void *argument)
{
  /* USER CODE BEGIN Sync_init */
  /* Infinite loop */
  for(;;)
  {
	  	osEventFlagsWait(mode_event_flags, SYNC_FLAG, osFlagsWaitAny, osWaitForever);
	  	send_ACK();

	  	uint8_t key;
	  	uint8_t key_index = 0;
	  	uint8_t expected_key_value = 0xFF;
	  	uint8_t rtc_buffer_size = 9;
	  	ERROR_STRUCT reset_cause;

	  	// Wait for 0xFF to be received
	  	HAL_UART_AbortReceive(&huart1);
	  	do
	  	{
	  		HAL_UART_Receive(&huart1, UART_RX_BUFFER, rtc_buffer_size, UART_TIMEOUT_MS);
	  		key = UART_RX_BUFFER[key_index];
	  	} while (key != expected_key_value);

	  	calibrateRTC(UART_RX_BUFFER);
	  	HAL_UART_Receive_IT(&huart1, UART_RX_BUFFER, 1);
	  	osDelay(SYNC_DELAY);
	  	reset_cause = get_reset_cause();
	  	create_sync_packet(reset_cause);
  }
  /* USER CODE END Sync_init */
}
